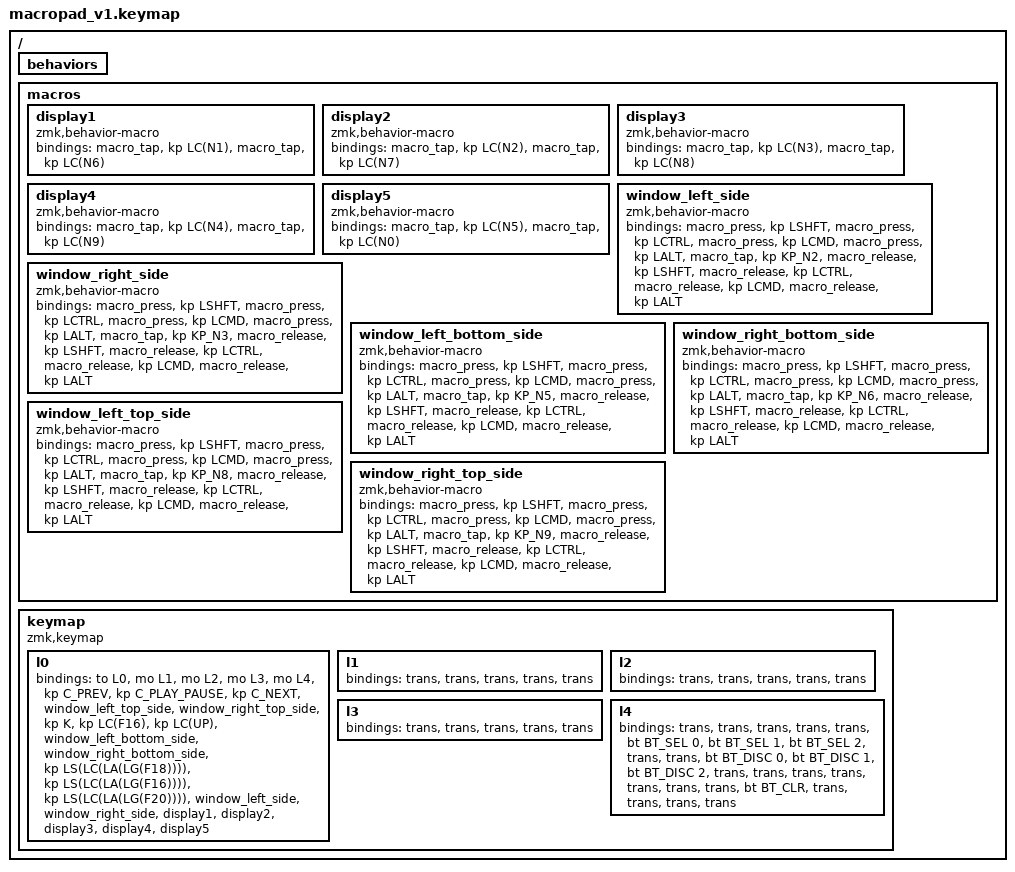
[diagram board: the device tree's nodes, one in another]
#include <behaviors.dtsi>
#include <dt-bindings/zmk/keys.h>
#include <dt-bindings/zmk/bt.h>

#define L0 0
#define L1 1
#define L2 2
#define L3 3
#define L4 4


/ {

    behaviors {

    };

    macros {
        display1: display1 {
            compatible = "zmk,behavior-macro";
            #binding-cells = <0>;
            bindings =  <&macro_tap &kp LC(N1)>,
                        <&macro_tap &kp LC(N6)>;
        };
        display2: display2 {
            compatible = "zmk,behavior-macro";
            #binding-cells = <0>;
            bindings =  <&macro_tap &kp LC(N2)>,
                        <&macro_tap &kp LC(N7)>;
        };
        display3: display3 {
            compatible = "zmk,behavior-macro";
            #binding-cells = <0>;
            bindings =  <&macro_tap &kp LC(N3)>,
                        <&macro_tap &kp LC(N8)>;
        };
        display4: display4 {
            compatible = "zmk,behavior-macro";
            #binding-cells = <0>;
            bindings =  <&macro_tap &kp LC(N4)>,
                        <&macro_tap &kp LC(N9)>;
        };
        display5: display5 {
            compatible = "zmk,behavior-macro";
            #binding-cells = <0>;
            bindings =  <&macro_tap &kp LC(N5)>,
                        <&macro_tap &kp LC(N0)>;
        };
        window_left_side: window_left_side {
            compatible = "zmk,behavior-macro";
            #binding-cells = <0>;
            bindings = <
                &macro_press &kp LSHFT
                &macro_press &kp LCTRL
                &macro_press &kp LCMD
                &macro_press &kp LALT
                &macro_tap &kp KP_N2
                &macro_release &kp LSHFT
                &macro_release &kp LCTRL
                &macro_release &kp LCMD
                &macro_release &kp LALT
            >;
        };
        window_right_side: window_right_side {
            compatible = "zmk,behavior-macro";
            #binding-cells = <0>;
            bindings = <
                &macro_press &kp LSHFT
                &macro_press &kp LCTRL
                &macro_press &kp LCMD
                &macro_press &kp LALT
                &macro_tap &kp KP_N3
                &macro_release &kp LSHFT
                &macro_release &kp LCTRL
                &macro_release &kp LCMD
                &macro_release &kp LALT
            >;
        };
        window_left_bottom_side: window_left_bottom_side {
            compatible = "zmk,behavior-macro";
            #binding-cells = <0>;
            bindings = <
                &macro_press &kp LSHFT
                &macro_press &kp LCTRL
                &macro_press &kp LCMD
                &macro_press &kp LALT
                &macro_tap &kp KP_N5
                &macro_release &kp LSHFT
                &macro_release &kp LCTRL
                &macro_release &kp LCMD
                &macro_release &kp LALT
            >;
        };
        window_right_bottom_side: window_right_bottom_side {
            compatible = "zmk,behavior-macro";
            #binding-cells = <0>;
            bindings = <
                &macro_press &kp LSHFT
                &macro_press &kp LCTRL
                &macro_press &kp LCMD
                &macro_press &kp LALT
                &macro_tap &kp KP_N6
                &macro_release &kp LSHFT
                &macro_release &kp LCTRL
                &macro_release &kp LCMD
                &macro_release &kp LALT
            >;
        };
        window_left_top_side: window_left_top_side {
            compatible = "zmk,behavior-macro";
            #binding-cells = <0>;
            bindings = <
                &macro_press &kp LSHFT
                &macro_press &kp LCTRL
                &macro_press &kp LCMD
                &macro_press &kp LALT
                &macro_tap &kp KP_N8
                &macro_release &kp LSHFT
                &macro_release &kp LCTRL
                &macro_release &kp LCMD
                &macro_release &kp LALT
            >;
        };
        window_right_top_side: window_right_top_side {
            compatible = "zmk,behavior-macro";
            #binding-cells = <0>;
            bindings = <
                &macro_press &kp LSHFT
                &macro_press &kp LCTRL
                &macro_press &kp LCMD
                &macro_press &kp LALT
                &macro_tap &kp KP_N9
                &macro_release &kp LSHFT
                &macro_release &kp LCTRL
                &macro_release &kp LCMD
                &macro_release &kp LALT
            >;
        };
    };

    keymap {
        compatible = "zmk,keymap";

        l0 {
            bindings = <
                &to L0 &mo L1 &mo L2 &mo L3 &mo L4
                &kp C_PREV &kp C_PLAY_PAUSE &kp C_NEXT &window_left_top_side &window_right_top_side
                &kp K &kp LC(F16) &kp LC(UP) &window_left_bottom_side &window_right_bottom_side
                &kp LS(LC(LA(LG(F18)))) &kp LS(LC(LA(LG(F16)))) &kp LS(LC(LA(LG(F20)))) &window_left_side &window_right_side
                &display1 &display2 &display3 &display4 &display5
            >;
        };


        l1 {
            bindings = <
                &trans &trans &trans &trans &trans
            >;    
        };

        l2 {
            bindings = <
                &trans &trans &trans &trans &trans
            >;    
        };

        l3 {
            bindings = <
                &trans &trans &trans &trans &trans
            >;    
        };

        l4 {
            bindings = <
                &trans &trans &trans &trans &trans
                &bt BT_SEL 0 &bt BT_SEL 1 &bt BT_SEL 2 &trans &trans
                &bt BT_DISC 0 &bt BT_DISC 1 &bt BT_DISC 2 &trans &trans
                &trans &trans &trans &trans &trans
                &bt BT_CLR &trans &trans &trans &trans
            >;  
        };

    };
    
};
